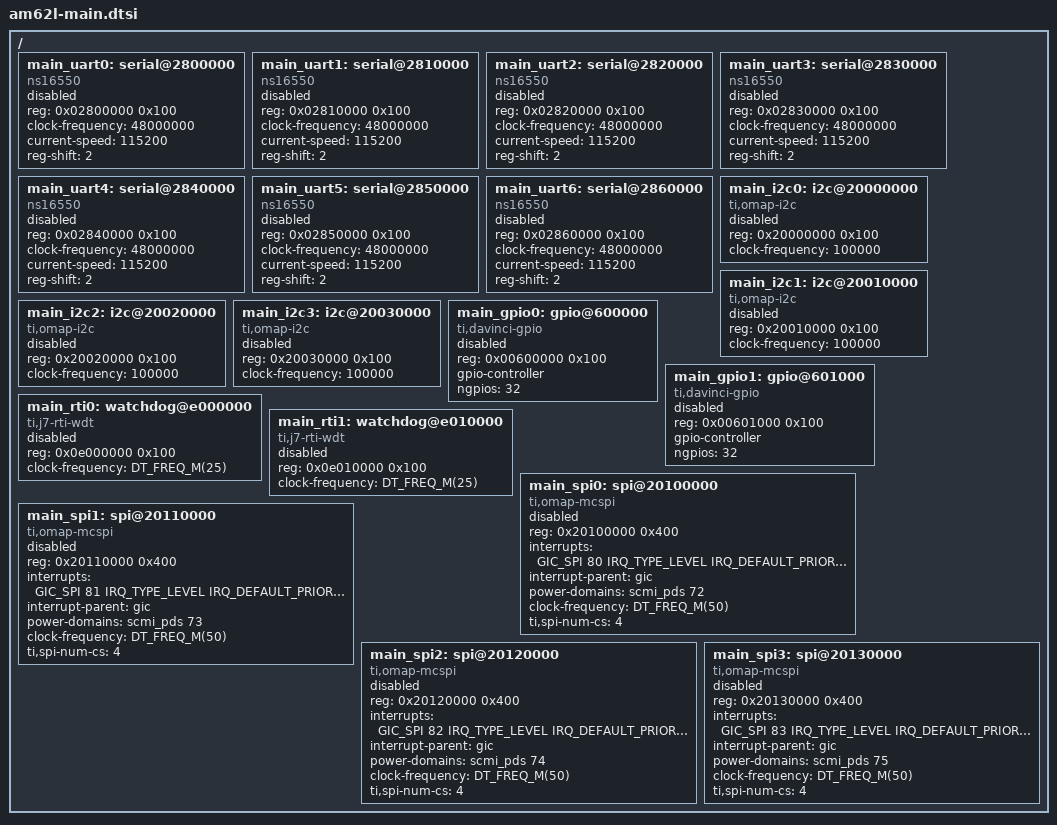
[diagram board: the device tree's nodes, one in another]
// SPDX-License-Identifier: GPL-2.0-only OR MIT
/*
 * Device Tree Source for AM62L SoC Family Main Domain peripherals
 *
 * Copyright (C) 2025 Texas Instruments Incorporated - https://www.ti.com/
 */

/ {
	main_uart0: serial@2800000 {
		compatible = "ns16550";
		reg = <0x02800000 0x100>;
		clock-frequency = <48000000>;
		current-speed = <115200>;
		reg-shift = <2>;
		status = "disabled";
	};

	main_uart1: serial@2810000 {
		compatible = "ns16550";
		reg = <0x02810000 0x100>;
		clock-frequency = <48000000>;
		current-speed = <115200>;
		reg-shift = <2>;
		status = "disabled";
	};

	main_uart2: serial@2820000 {
		compatible = "ns16550";
		reg = <0x02820000 0x100>;
		clock-frequency = <48000000>;
		current-speed = <115200>;
		reg-shift = <2>;
		status = "disabled";
	};

	main_uart3: serial@2830000 {
		compatible = "ns16550";
		reg = <0x02830000 0x100>;
		clock-frequency = <48000000>;
		current-speed = <115200>;
		reg-shift = <2>;
		status = "disabled";
	};

	main_uart4: serial@2840000 {
		compatible = "ns16550";
		reg = <0x02840000 0x100>;
		clock-frequency = <48000000>;
		current-speed = <115200>;
		reg-shift = <2>;
		status = "disabled";
	};

	main_uart5: serial@2850000 {
		compatible = "ns16550";
		reg = <0x02850000 0x100>;
		clock-frequency = <48000000>;
		current-speed = <115200>;
		reg-shift = <2>;
		status = "disabled";
	};

	main_uart6: serial@2860000 {
		compatible = "ns16550";
		reg = <0x02860000 0x100>;
		clock-frequency = <48000000>;
		current-speed = <115200>;
		reg-shift = <2>;
		status = "disabled";
	};

	main_i2c0: i2c@20000000 {
		compatible = "ti,omap-i2c";
		reg = <0x20000000 0x100>;
		clock-frequency = <100000>;
		#address-cells = <1>;
		#size-cells = <0>;
		status = "disabled";
	};

	main_i2c1: i2c@20010000 {
		compatible = "ti,omap-i2c";
		reg = <0x20010000 0x100>;
		clock-frequency = <100000>;
		#address-cells = <1>;
		#size-cells = <0>;
		status = "disabled";
	};

	main_i2c2: i2c@20020000 {
		compatible = "ti,omap-i2c";
		reg = <0x20020000 0x100>;
		clock-frequency = <100000>;
		#address-cells = <1>;
		#size-cells = <0>;
		status = "disabled";
	};

	main_i2c3: i2c@20030000 {
		compatible = "ti,omap-i2c";
		reg = <0x20030000 0x100>;
		clock-frequency = <100000>;
		#address-cells = <1>;
		#size-cells = <0>;
		status = "disabled";
	};

	main_gpio0: gpio@600000 {
		compatible = "ti,davinci-gpio";
		reg = <0x00600000 0x100>;
		gpio-controller;
		#gpio-cells = <2>;
		/* FIXME: Enable all GPIOs */
		ngpios = <32>;
		status = "disabled";
	};

	main_gpio1: gpio@601000 {
		compatible = "ti,davinci-gpio";
		reg = <0x00601000 0x100>;
		gpio-controller;
		#gpio-cells = <2>;
		/* FIXME: Enable all GPIOs */
		ngpios = <32>;
		status = "disabled";
	};

	main_rti0: watchdog@e000000 {
		compatible = "ti,j7-rti-wdt";
		reg = <0x0e000000 0x100>;
		clock-frequency = <DT_FREQ_M(25)>;
		status = "disabled";
	};

	main_rti1: watchdog@e010000 {
		compatible = "ti,j7-rti-wdt";
		reg = <0x0e010000 0x100>;
		clock-frequency = <DT_FREQ_M(25)>;
		status = "disabled";
	};

	main_spi0: spi@20100000 {
		compatible = "ti,omap-mcspi";
		reg = <0x20100000 0x400>;
		interrupts = <GIC_SPI 80 IRQ_TYPE_LEVEL IRQ_DEFAULT_PRIORITY>;
		interrupt-parent = <&gic>;
		#address-cells = <1>;
		#size-cells = <0>;
		power-domains = <&scmi_pds 72>;
		clock-frequency = <DT_FREQ_M(50)>;
//		clocks = <&scmi_clk 299>;
		ti,spi-num-cs = <4>;
		status = "disabled";
	};

	main_spi1: spi@20110000 {
		compatible = "ti,omap-mcspi";
		reg = <0x20110000 0x400>;
		interrupts = <GIC_SPI 81 IRQ_TYPE_LEVEL IRQ_DEFAULT_PRIORITY>;
		interrupt-parent = <&gic>;
		#address-cells = <1>;
		#size-cells = <0>;
		power-domains = <&scmi_pds 73>;
		clock-frequency = <DT_FREQ_M(50)>;
//		clocks = <&scmi_clk 302>;
		ti,spi-num-cs = <4>;
		status = "disabled";
	};

	main_spi2: spi@20120000 {
		compatible = "ti,omap-mcspi";
		reg = <0x20120000 0x400>;
		interrupts = <GIC_SPI 82 IRQ_TYPE_LEVEL IRQ_DEFAULT_PRIORITY>;
		interrupt-parent = <&gic>;
		#address-cells = <1>;
		#size-cells = <0>;
		power-domains = <&scmi_pds 74>;
		clock-frequency = <DT_FREQ_M(50)>;
//		clocks = <&scmi_clk 305>;
		ti,spi-num-cs = <4>;
		status = "disabled";
	};

	main_spi3: spi@20130000 {
		compatible = "ti,omap-mcspi";
		reg = <0x20130000 0x400>;
		interrupts = <GIC_SPI 83 IRQ_TYPE_LEVEL IRQ_DEFAULT_PRIORITY>;
		interrupt-parent = <&gic>;
		#address-cells = <1>;
		#size-cells = <0>;
		power-domains = <&scmi_pds 75>;
		clock-frequency = <DT_FREQ_M(50)>;
//		clocks = <&scmi_clk 308>;
		ti,spi-num-cs = <4>;
		status = "disabled";
	};
};
